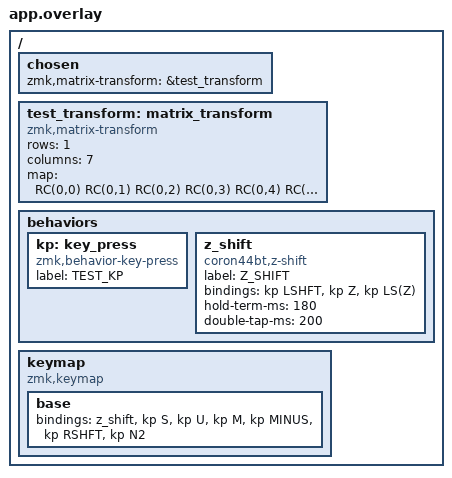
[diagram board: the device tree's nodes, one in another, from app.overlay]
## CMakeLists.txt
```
cmake_minimum_required(VERSION 3.20.0)
if(NOT DEFINED ZMK_SOURCE_DIR OR NOT DEFINED OSKEY_SOURCE_DIR)
  message(FATAL_ERROR "Set the pinned ZMK_SOURCE_DIR and OSKEY_SOURCE_DIR")
endif()
set(CONFIG_APPLICATION_DEFINED_SYSCALL true)
list(APPEND DTS_ROOT ${ZMK_SOURCE_DIR}/app)
list(APPEND SYSCALL_INCLUDE_DIRS ${ZMK_SOURCE_DIR}/app/include)
find_package(Zephyr REQUIRED HINTS $ENV{ZEPHYR_BASE})
project(coron44bt_z_shift_simulation)
target_include_directories(app PRIVATE ${ZMK_SOURCE_DIR}/app/include ${OSKEY_SOURCE_DIR}/include)
zephyr_linker_sources(RODATA
  ${ZMK_SOURCE_DIR}/app/include/linker/zmk-events.ld
)
zephyr_linker_sources(SECTIONS ${CMAKE_CURRENT_SOURCE_DIR}/behaviors.ld)
target_sources(app PRIVATE
  src/main.c
  src/keymap.c
  ${ZMK_SOURCE_DIR}/app/src/behavior.c
  ${ZMK_SOURCE_DIR}/app/src/behaviors/behavior_key_press.c
  ${ZMK_SOURCE_DIR}/app/src/hid.c
  ${ZMK_SOURCE_DIR}/app/src/hid_listener.c
  ${ZMK_SOURCE_DIR}/app/src/event_manager.c
  ${ZMK_SOURCE_DIR}/app/src/events/keycode_state_changed.c
  ${ZMK_SOURCE_DIR}/app/src/events/position_state_changed.c
  ${ZMK_SOURCE_DIR}/app/src/events/endpoint_changed.c
)
```

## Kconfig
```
rsource "../usjis/Kconfig"

config ZMK_BEHAVIOR_METADATA
    bool
    default y
```

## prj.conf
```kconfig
CONFIG_LOG=y
CONFIG_LOG_MODE_IMMEDIATE=y
CONFIG_HEAP_MEM_POOL_SIZE=8192
CONFIG_MAIN_STACK_SIZE=8192
CONFIG_ASSERT=y
# Use 1ms ticks for the native harness. Its coarse default tick can round a
# 190ms sleep up to the 200ms boundary; the hardware tick is finer still.
CONFIG_SYS_CLOCK_TICKS_PER_SEC=1000
CONFIG_ZMK_USJIS=y
CONFIG_ZMK_USJIS_DEFAULT_ENABLED=y
CONFIG_ZMK_USJIS_LAYER_MASK=0
```

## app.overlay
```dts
#include <dt-bindings/zmk/keys.h>
#include <dt-bindings/zmk/matrix_transform.h>
/ {
    chosen {
        zmk,matrix-transform = &test_transform;
    };
    test_transform: matrix_transform {
        compatible = "zmk,matrix-transform";
        rows = <1>;
        columns = <7>;
        map = <RC(0,0) RC(0,1) RC(0,2) RC(0,3) RC(0,4) RC(0,5) RC(0,6)>;
    };
    behaviors {
        kp: key_press {
            compatible = "zmk,behavior-key-press";
            label = "TEST_KP";
            #binding-cells = <1>;
        };
        z_shift: z_shift {
            compatible = "coron44bt,z-shift";
            label = "Z_SHIFT";
            #binding-cells = <0>;
            bindings = <&kp LSHFT>, <&kp Z>, <&kp LS(Z)>;
            hold-term-ms = <180>;
            double-tap-ms = <200>;
        };
    };
    keymap {
        compatible = "zmk,keymap";
        base {
            bindings = <&z_shift &kp S &kp U &kp M &kp MINUS &kp RSHFT &kp N2>;
        };
    };
};
```

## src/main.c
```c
/* SPDX-License-Identifier: MIT */
#include <stdio.h>
#include <stdlib.h>
#include <string.h>
#include <zephyr/kernel.h>
#include <zephyr/logging/log.h>
#include <zmk/hid.h>
#include <zmk/event_manager.h>
#include <zmk/events/position_state_changed.h>
#include <zmk/usjis.h>
#include <oskey/os_state.h>

LOG_MODULE_REGISTER(zmk, CONFIG_ZMK_LOG_LEVEL);
uint8_t zmk_oskey_get_os(void) { return OSKEY_OS_WINDOWS; }

static unsigned assertions, scenarios, total_reports, reports;
static const char *scenario = "startup";
struct report { uint8_t mods, keys[6]; };
static struct report captured[128];

#define CHECK(test) do { assertions++; if (!(test)) { \
    printf("FAIL %s line=%d: %s\n", scenario, __LINE__, #test); exit(1); \
} } while (0)

int zmk_endpoint_send_report(uint16_t page) {
    CHECK(page == HID_USAGE_KEY);
    CHECK(reports < ARRAY_SIZE(captured));
    const struct zmk_hid_keyboard_report *r = zmk_hid_get_keyboard_report();
    captured[reports].mods = r->body.modifiers;
    memcpy(captured[reports].keys, r->body.keys, 6);
    reports++;
    total_reports++;
    printf("REPORT %s %u mods=%02x keys=", scenario, reports, r->body.modifiers);
    for (int i=0;i<6;i++) { if(r->body.keys[i]) printf("%02x,",r->body.keys[i]); }
    printf("\n");
    return 0;
}

static void expect(unsigned index, uint8_t mods, uint8_t key) {
    CHECK(index > 0 && index <= reports);
    const struct report *r = &captured[index-1];
    CHECK(r->mods == mods);
    unsigned n=0;
    for(int i=0;i<6;i++) { if(r->keys[i]) { CHECK(r->keys[i] == key); n++; } }
    CHECK(n == (key ? 1 : 0));
}

static void key(unsigned position, bool down) {
    CHECK(raise_zmk_position_state_changed((struct zmk_position_state_changed){
        .source = ZMK_POSITION_STATE_CHANGE_SOURCE_LOCAL, .position=position,
        .state=down, .timestamp=k_uptime_get(),
    }) >= 0);
}
static void begin(const char *name) { scenario=name; reports=0; scenarios++; }
static void idle(void) {
    CHECK(zmk_hid_get_keyboard_report()->body.modifiers == 0);
    CHECK(zmk_hid_get_explicit_mods() == 0);
    for(int i=0;i<6;i++) CHECK(zmk_hid_get_keyboard_report()->body.keys[i] == 0);
    CHECK(zmk_usjis_active_entries() == 0);
    printf("PASS %s\n",scenario);
}

int main(void) {
    setvbuf(stdout,NULL,_IOLBF,0);
    CHECK(zmk_usjis_listener_order_ok());

    begin("z-s-immediate-shift-before-s");
    key(0,true); key(1,true);
    CHECK(reports == 2); expect(1,2,0); expect(2,2,0x16);
    key(0,false); expect(3,0,0x16); key(1,false); expect(4,0,0); idle();

    begin("z-s-other-key-released-first");
    key(0,true); k_msleep(20); key(1,true); expect(2,2,0x16);
    key(1,false); expect(3,2,0); key(0,false); expect(4,0,0); idle();

    begin("single-tap-lowercase-z");
    key(0,true); k_msleep(20); key(0,false); CHECK(reports == 0);
    k_msleep(220); CHECK(reports == 2); expect(1,0,0x1d); expect(2,0,0); idle();

    begin("released-z-before-u-keeps-order");
    key(0,true); k_msleep(10); key(0,false); key(2,true);
    CHECK(reports == 3); expect(1,0,0x1d); expect(2,0,0); expect(3,0,0x18);
    key(2,false); expect(4,0,0); idle();

    begin("double-tap-uppercase-on-second-press");
    key(0,true); k_msleep(20); key(0,false); k_msleep(30); key(0,true);
    CHECK(reports == 1); expect(1,2,0x1d);
    key(0,false); expect(2,0,0); idle();

    begin("relaxed-double-tap-190ms-after-release");
    key(0,true); k_msleep(20); key(0,false); k_msleep(190); key(0,true);
    CHECK(reports == 1); expect(1,2,0x1d);
    key(0,false); expect(2,0,0); idle();

    begin("expired-double-tap-is-two-lowercase-z");
    key(0,true); key(0,false); k_msleep(220);
    key(0,true); key(0,false); k_msleep(220);
    CHECK(reports == 4); expect(1,0,0x1d); expect(2,0,0);
    expect(3,0,0x1d); expect(4,0,0); idle();

    begin("isolated-hold-shift-at-180ms");
    key(0,true); k_msleep(190); CHECK(reports == 1); expect(1,2,0);
    key(0,false); expect(2,0,0); idle();

    begin("held-shift-multiple-letters-no-stray-z");
    key(0,true);
    const unsigned word[] = {1,2,3,2};
    const uint8_t usages[] = {0x16,0x18,0x10,0x18};
    for(unsigned i=0;i<ARRAY_SIZE(word);i++) {
        key(word[i],true); expect(reports,2,usages[i]);
        key(word[i],false); expect(reports,2,0);
    }
    key(0,false); CHECK(reports == 10); expect(10,0,0); idle();

    begin("duplicate-down-does-not-become-uppercase");
    key(0,true); key(0,true); key(0,false); k_msleep(220);
    CHECK(reports == 2); expect(1,0,0x1d); expect(2,0,0); idle();

    begin("external-right-shift-survives-z-shift-release");
    key(5,true); key(0,true); key(1,true); expect(reports,0x22,0x16);
    key(1,false); key(0,false); expect(reports,0x20,0);
    key(5,false); expect(reports,0,0); idle();

    begin("windows-jis-at-with-z-shift");
    key(0,true); key(6,true); expect(2,0,0x2f);
    key(0,false); expect(3,0,0x2f); key(6,false); expect(4,0,0); idle();

    begin("second-tap-held-remains-uppercase-without-extra-presses");
    key(0,true); key(0,false); k_msleep(30); key(0,true);
    expect(1,2,0x1d); k_msleep(300); CHECK(reports == 1);
    key(0,false); expect(2,0,0); idle();

    k_msleep(220); CHECK(reports == 2); idle();
    printf("Z_SHIFT_HID_PASS scenarios=%u assertions=%u reports=%u\n",scenarios,assertions,total_reports);
    exit(0);
}
```

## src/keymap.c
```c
/* SPDX-License-Identifier: MIT */
/* The hardware/keymap boundary: dispatch positions through the real behavior
 * API. This listener is placed after Z_SHIFT, just as in the firmware. */
#include <zephyr/device.h>
#include <zmk/behavior.h>
#include <zmk/event_manager.h>
#include <zmk/events/position_state_changed.h>
#include <dt-bindings/zmk/keys.h>

static const struct zmk_behavior_binding keys[] = {
    {.behavior_dev = DEVICE_DT_NAME(DT_NODELABEL(z_shift))},
    {.behavior_dev = DEVICE_DT_NAME(DT_NODELABEL(kp)), .param1 = S},
    {.behavior_dev = DEVICE_DT_NAME(DT_NODELABEL(kp)), .param1 = U},
    {.behavior_dev = DEVICE_DT_NAME(DT_NODELABEL(kp)), .param1 = M},
    {.behavior_dev = DEVICE_DT_NAME(DT_NODELABEL(kp)), .param1 = MINUS},
    {.behavior_dev = DEVICE_DT_NAME(DT_NODELABEL(kp)), .param1 = RSHFT},
    {.behavior_dev = DEVICE_DT_NAME(DT_NODELABEL(kp)), .param1 = N2},
};

uint32_t zmk_keymap_layer_state(void) { return 1; }

static int dispatch(const zmk_event_t *eh) {
    const struct zmk_position_state_changed *event = as_zmk_position_state_changed(eh);
    if (!event || event->position >= ARRAY_SIZE(keys)) { return ZMK_EV_EVENT_BUBBLE; }
    struct zmk_behavior_binding_event binding_event = {
        .position = event->position, .timestamp = event->timestamp,
    };
    return zmk_behavior_invoke_binding(&keys[event->position], binding_event, event->state);
}

ZMK_LISTENER(keymap, dispatch);
ZMK_SUBSCRIPTION(keymap, zmk_position_state_changed);
```
